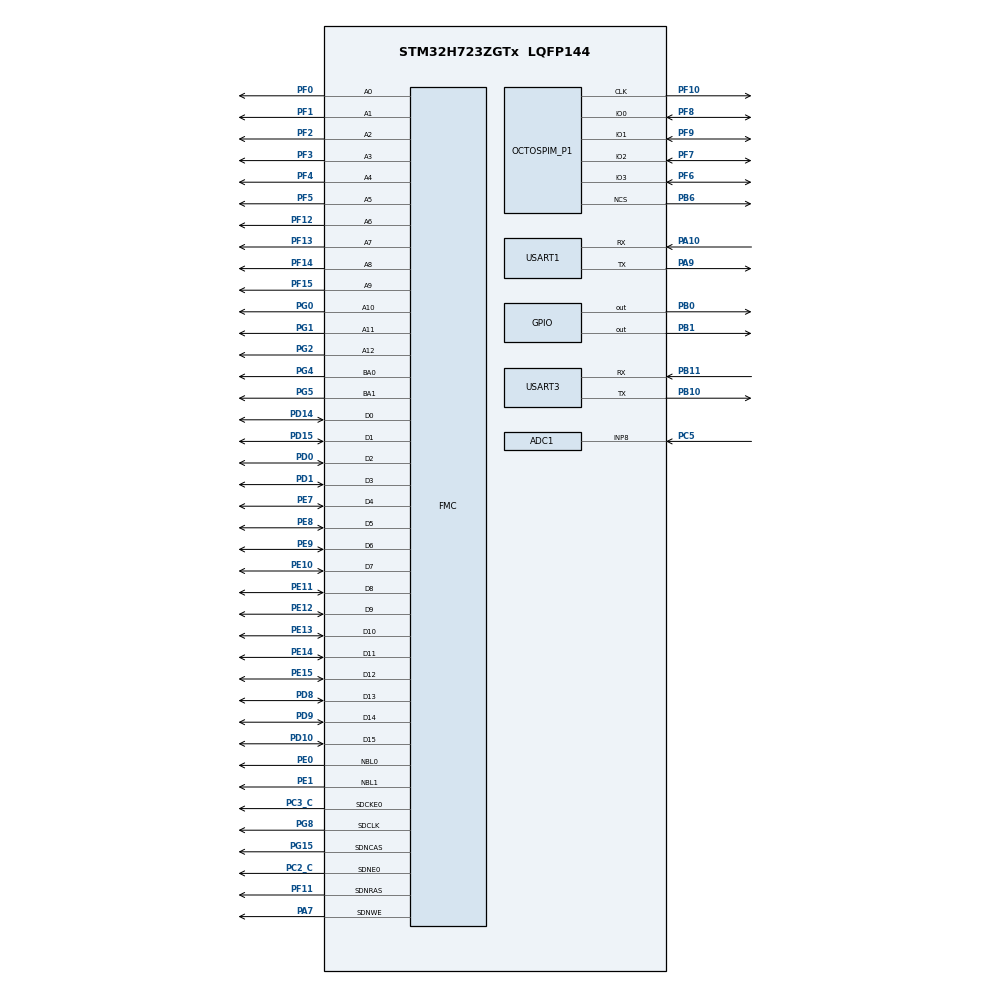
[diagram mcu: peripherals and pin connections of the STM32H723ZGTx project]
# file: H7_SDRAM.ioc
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ADC1.Channel-0\#ChannelRegularConversion=ADC_CHANNEL_8
ADC1.ClockPrescaler=ADC_CLOCK_ASYNC_DIV4
ADC1.ConversionDataManagement=ADC_CONVERSIONDATA_DMA_CIRCULAR
ADC1.ExternalTrigConv=ADC_EXTERNALTRIG_T3_TRGO
ADC1.NbrOfConversionFlag=1
ADC1.OffsetNumber-0\#ChannelRegularConversion=ADC_OFFSET_NONE
ADC1.OffsetSignedSaturation-0\#ChannelRegularConversion=DISABLE
ADC1.Rank-0\#ChannelRegularConversion=1
ADC1.SamplingTime-0\#ChannelRegularConversion=ADC_SAMPLETIME_8CYCLES_5
ADC1.master=1
CORTEX_M7.AccessPermission_S-Cortex_Memory_Protection_Unit_Region1_Settings_S=MPU_REGION_FULL_ACCESS
CORTEX_M7.AccessPermission_S-Cortex_Memory_Protection_Unit_Region2_Settings_S=MPU_REGION_FULL_ACCESS
CORTEX_M7.AccessPermission_S-Cortex_Memory_Protection_Unit_Region3_Settings_S=MPU_REGION_FULL_ACCESS
CORTEX_M7.AccessPermission_S-Cortex_Memory_Protection_Unit_Region5_Settings_S=MPU_REGION_FULL_ACCESS
CORTEX_M7.AccessPermission_Spec=MPU_REGION_FULL_ACCESS
CORTEX_M7.BaseAddress_S-Cortex_Memory_Protection_Unit_Region1_Settings_S=0x60000000
CORTEX_M7.BaseAddress_S-Cortex_Memory_Protection_Unit_Region2_Settings_S=0x30000000
CORTEX_M7.BaseAddress_S-Cortex_Memory_Protection_Unit_Region3_Settings_S=0x38000000
CORTEX_M7.BaseAddress_S-Cortex_Memory_Protection_Unit_Region5_Settings_S=0xC0000000
CORTEX_M7.BaseAddress_Spec=0x24000000
CORTEX_M7.CPU_DCache=Enabled
CORTEX_M7.CPU_ICache=Enabled
CORTEX_M7.DisableExec_S-Cortex_Memory_Protection_Unit_Region1_Settings_S=MPU_INSTRUCTION_ACCESS_ENABLE
CORTEX_M7.DisableExec_S-Cortex_Memory_Protection_Unit_Region2_Settings_S=MPU_INSTRUCTION_ACCESS_ENABLE
CORTEX_M7.DisableExec_S-Cortex_Memory_Protection_Unit_Region3_Settings_S=MPU_INSTRUCTION_ACCESS_ENABLE
CORTEX_M7.DisableExec_Spec=MPU_INSTRUCTION_ACCESS_ENABLE
CORTEX_M7.Enable_S-Cortex_Memory_Protection_Unit_Region1_Settings_S=MPU_REGION_ENABLE
CORTEX_M7.Enable_S-Cortex_Memory_Protection_Unit_Region2_Settings_S=MPU_REGION_ENABLE
CORTEX_M7.Enable_S-Cortex_Memory_Protection_Unit_Region3_Settings_S=MPU_REGION_ENABLE
CORTEX_M7.Enable_S-Cortex_Memory_Protection_Unit_Region4_Settings_S=__NULL
CORTEX_M7.Enable_S-Cortex_Memory_Protection_Unit_Region5_Settings_S=MPU_REGION_ENABLE
CORTEX_M7.IsBufferable_S-Cortex_Memory_Protection_Unit_Region1_Settings_S=MPU_ACCESS_BUFFERABLE
CORTEX_M7.IsBufferable_S-Cortex_Memory_Protection_Unit_Region2_Settings_S=MPU_ACCESS_BUFFERABLE
CORTEX_M7.IsBufferable_Spec=MPU_ACCESS_BUFFERABLE
CORTEX_M7.IsCacheable_S-Cortex_Memory_Protection_Unit_Region1_Settings_S=MPU_ACCESS_NOT_CACHEABLE
CORTEX_M7.IsCacheable_S-Cortex_Memory_Protection_Unit_Region2_Settings_S=MPU_ACCESS_CACHEABLE
CORTEX_M7.IsCacheable_S-Cortex_Memory_Protection_Unit_Region3_Settings_S=MPU_ACCESS_CACHEABLE
CORTEX_M7.IsCacheable_S-Cortex_Memory_Protection_Unit_Region5_Settings_S=MPU_ACCESS_CACHEABLE
CORTEX_M7.IsCacheable_Spec=MPU_ACCESS_CACHEABLE
CORTEX_M7.IsShareable_Spec=MPU_ACCESS_NOT_SHAREABLE
CORTEX_M7.Size_S-Cortex_Memory_Protection_Unit_Region1_Settings_S=MPU_REGION_SIZE_64KB
CORTEX_M7.Size_S-Cortex_Memory_Protection_Unit_Region2_Settings_S=MPU_REGION_SIZE_64KB
CORTEX_M7.Size_S-Cortex_Memory_Protection_Unit_Region3_Settings_S=MPU_REGION_SIZE_64KB
CORTEX_M7.Size_S-Cortex_Memory_Protection_Unit_Region5_Settings_S=MPU_REGION_SIZE_32MB
CORTEX_M7.Size_Spec=MPU_REGION_SIZE_512KB
CORTEX_M7.SubRegionDisable_S-Cortex_Memory_Protection_Unit_Region1_Settings_S=0x00
CORTEX_M7.SubRegionDisable_Spec=0xE0
CORTEX_M7.TypeExtField_S-Cortex_Memory_Protection_Unit_Region1_Settings_S=MPU_TEX_LEVEL1
CORTEX_M7.TypeExtField_S-Cortex_Memory_Protection_Unit_Region5_Settings_S=MPU_TEX_LEVEL1
CORTEX_M7.TypeExtField_Spec=MPU_TEX_LEVEL1
CORTEX_M7.default_mode_Activation=1
Dma.ADC1.0.Direction=DMA_PERIPH_TO_MEMORY
Dma.ADC1.0.EventEnable=DISABLE
Dma.ADC1.0.FIFOMode=DMA_FIFOMODE_DISABLE
Dma.ADC1.0.Instance=DMA1_Stream0
Dma.ADC1.0.MemDataAlignment=DMA_MDATAALIGN_HALFWORD
Dma.ADC1.0.MemInc=DMA_MINC_ENABLE
Dma.ADC1.0.Mode=DMA_CIRCULAR
Dma.ADC1.0.PeriphDataAlignment=DMA_PDATAALIGN_HALFWORD
Dma.ADC1.0.PeriphInc=DMA_PINC_DISABLE
Dma.ADC1.0.Polarity=HAL_DMAMUX_REQ_GEN_RISING
Dma.ADC1.0.Priority=DMA_PRIORITY_LOW
Dma.ADC1.0.RequestNumber=1
Dma.ADC1.0.SignalID=NONE
Dma.ADC1.0.SyncEnable=DISABLE
Dma.ADC1.0.SyncPolarity=HAL_DMAMUX_SYNC_NO_EVENT
Dma.ADC1.0.SyncRequestNumber=1
Dma.ADC1.0.SyncSignalID=NONE
Dma.Request0=ADC1
Dma.Request1=USART1_RX
Dma.Request2=USART3_RX
Dma.USART1_RX.1.Direction=DMA_PERIPH_TO_MEMORY
Dma.USART1_RX.1.EventEnable=DISABLE
Dma.USART1_RX.1.FIFOMode=DMA_FIFOMODE_DISABLE
Dma.USART1_RX.1.Instance=DMA1_Stream1
Dma.USART1_RX.1.MemDataAlignment=DMA_MDATAALIGN_BYTE
Dma.USART1_RX.1.MemInc=DMA_MINC_ENABLE
Dma.USART1_RX.1.Mode=DMA_NORMAL
Dma.USART1_RX.1.PeriphDataAlignment=DMA_PDATAALIGN_BYTE
Dma.USART1_RX.1.PeriphInc=DMA_PINC_DISABLE
Dma.USART1_RX.1.Polarity=HAL_DMAMUX_REQ_GEN_RISING
Dma.USART1_RX.1.Priority=DMA_PRIORITY_HIGH
Dma.USART1_RX.1.RequestNumber=1
Dma.USART1_RX.1.SignalID=NONE
Dma.USART1_RX.1.SyncEnable=DISABLE
Dma.USART1_RX.1.SyncPolarity=HAL_DMAMUX_SYNC_NO_EVENT
Dma.USART1_RX.1.SyncRequestNumber=1
Dma.USART1_RX.1.SyncSignalID=NONE
Dma.USART3_RX.2.Direction=DMA_PERIPH_TO_MEMORY
Dma.USART3_RX.2.EventEnable=DISABLE
Dma.USART3_RX.2.FIFOMode=DMA_FIFOMODE_DISABLE
Dma.USART3_RX.2.Instance=DMA1_Stream2
Dma.USART3_RX.2.MemDataAlignment=DMA_MDATAALIGN_BYTE
Dma.USART3_RX.2.MemInc=DMA_MINC_ENABLE
Dma.USART3_RX.2.Mode=DMA_NORMAL
Dma.USART3_RX.2.PeriphDataAlignment=DMA_PDATAALIGN_BYTE
Dma.USART3_RX.2.PeriphInc=DMA_PINC_DISABLE
Dma.USART3_RX.2.Polarity=HAL_DMAMUX_REQ_GEN_RISING
Dma.USART3_RX.2.Priority=DMA_PRIORITY_MEDIUM
Dma.USART3_RX.2.RequestNumber=1
Dma.USART3_RX.2.SignalID=NONE
Dma.USART3_RX.2.SyncEnable=DISABLE
Dma.USART3_RX.2.SyncPolarity=HAL_DMAMUX_SYNC_NO_EVENT
Dma.USART3_RX.2.SyncRequestNumber=1
Dma.USART3_RX.2.SyncSignalID=NONE
FMC.CASLatency1=FMC_SDRAM_CAS_LATENCY_3
FMC.ColumnBitsNumber1=FMC_SDRAM_COLUMN_BITS_NUM_9
FMC.ExitSelfRefreshDelay1=10
FMC.LoadToActiveDelay1=2
FMC.RCDDelay1=2
FMC.RPDelay1=3
FMC.RPDelay2=3
FMC.ReadBurst1=FMC_SDRAM_RBURST_ENABLE
FMC.ReadPipeDelay1=FMC_SDRAM_RPIPE_DELAY_1
FMC.ReadPipeDelay2=FMC_SDRAM_RPIPE_DELAY_1
FMC.RowCycleDelay1=9
FMC.RowCycleDelay2=9
FMC.SDClockPeriod1=FMC_SDRAM_CLOCK_PERIOD_2
FMC.SelfRefreshTime1=6
FMC.WriteRecoveryTime1=4
Mcu.Family=STM32H7
Mcu.Name=STM32H723ZGTx
Mcu.Package=LQFP144
NVIC.ADC_IRQn=true\:1\:0\:true\:false\:true\:true\:true\:true
NVIC.DMA1_Stream0_IRQn=true\:0\:0\:false\:false\:true\:false\:true\:true
NVIC.DMA1_Stream1_IRQn=true\:1\:0\:true\:false\:true\:false\:true\:true
NVIC.DMA1_Stream2_IRQn=true\:0\:0\:false\:false\:true\:false\:true\:true
NVIC.PriorityGroup=NVIC_PRIORITYGROUP_4
NVIC.USART1_IRQn=true\:0\:0\:false\:false\:true\:true\:true\:true
NVIC.USART3_IRQn=true\:0\:0\:false\:false\:true\:true\:true\:true
OCTOSPI1.ChipSelectHighTime=4
OCTOSPI1.ClockPrescaler=3
OCTOSPI1.DeviceSize=23
OCTOSPI1.FifoThreshold=4
OCTOSPI1.SampleShifting=HAL_OSPI_SAMPLE_SHIFTING_HALFCYCLE
PA10.Mode=Asynchronous
PA10.Signal=USART1_RX
PA7.Signal=FMC_SDNWE
PA9.Mode=Asynchronous
PA9.Signal=USART1_TX
PB0.GPIO_Speed=GPIO_SPEED_FREQ_VERY_HIGH
PB0.PinState=GPIO_PIN_SET
PB0.Signal=GPIO_Output
PB1.GPIO_Speed=GPIO_SPEED_FREQ_VERY_HIGH
PB1.PinState=GPIO_PIN_SET
PB1.Signal=GPIO_Output
PB10.Mode=Asynchronous
PB10.Signal=USART3_TX
PB11.Mode=Asynchronous
PB11.Signal=USART3_RX
PB6.Mode=OCTOSPI1_Port1_NCS
PB6.Signal=OCTOSPIM_P1_NCS
PC14-OSC32_IN.Mode=LSE-External-Oscillator
PC14-OSC32_IN.Signal=RCC_OSC32_IN
PC15-OSC32_OUT.Mode=LSE-External-Oscillator
PC15-OSC32_OUT.Signal=RCC_OSC32_OUT
PC2_C.Mode=SdramChipSelect1_1
PC2_C.Signal=FMC_SDNE0
PC3_C.Mode=SdramChipSelect1_1
PC3_C.Signal=FMC_SDCKE0
PC5.Signal=ADCx_INP8
PD0.Signal=FMC_D2_DA2
PD1.Signal=FMC_D3_DA3
PD10.Signal=FMC_D15_DA15
PD14.Signal=FMC_D0_DA0
PD15.Signal=FMC_D1_DA1
PD8.Signal=FMC_D13_DA13
PD9.Signal=FMC_D14_DA14
PE0.Signal=FMC_NBL0
PE1.Signal=FMC_NBL1
PE10.Signal=FMC_D7_DA7
PE11.Signal=FMC_D8_DA8
PE12.Signal=FMC_D9_DA9
PE13.Signal=FMC_D10_DA10
PE14.Signal=FMC_D11_DA11
PE15.Signal=FMC_D12_DA12
PE7.Signal=FMC_D4_DA4
PE8.Signal=FMC_D5_DA5
PE9.Signal=FMC_D6_DA6
PF0.Signal=FMC_A0
PF1.Signal=FMC_A1
PF10.Mode=O1_P1_CLK
PF10.Signal=OCTOSPIM_P1_CLK
PF11.Signal=FMC_SDNRAS
PF12.Signal=FMC_A6
PF13.Signal=FMC_A7
PF14.Signal=FMC_A8
PF15.Signal=FMC_A9
PF2.Signal=FMC_A2
PF3.Signal=FMC_A3
PF4.Signal=FMC_A4
PF5.Signal=FMC_A5
PF6.Mode=OCTOSPI1_IOL_Port1L
PF6.Signal=OCTOSPIM_P1_IO3
PF7.Mode=OCTOSPI1_IOL_Port1L
PF7.Signal=OCTOSPIM_P1_IO2
PF8.Mode=OCTOSPI1_IOL_Port1L
PF8.Signal=OCTOSPIM_P1_IO0
PF9.Mode=OCTOSPI1_IOL_Port1L
PF9.Signal=OCTOSPIM_P1_IO1
PG0.Signal=FMC_A10
PG1.Signal=FMC_A11
PG15.Signal=FMC_SDNCAS
PG2.Signal=FMC_A12
PG4.Signal=FMC_A14_BA0
PG5.Signal=FMC_A15_BA1
PG8.Signal=FMC_SDCLK
PH0-OSC_IN.Mode=HSE-External-Oscillator
PH0-OSC_IN.Signal=RCC_OSC_IN
PH1-OSC_OUT.Mode=HSE-External-Oscillator
PH1-OSC_OUT.Signal=RCC_OSC_OUT
ProjectManager.HeapSize=0x4000
ProjectManager.StackSize=0x4000
ProjectManager.TargetToolchain=MDK-ARM V5.32
RCC.ADCCLockSelection=RCC_ADCCLKSOURCE_CLKP
RCC.ADCFreq_Value=64000000
RCC.APB1Freq_Value=137500000
RCC.APB2Freq_Value=137500000
RCC.APB3Freq_Value=137500000
RCC.APB4Freq_Value=137500000
RCC.CortexFreq_Value=550000000
RCC.D1PPRE=RCC_APB3_DIV2
RCC.D2PPRE1=RCC_APB1_DIV2
RCC.D2PPRE2=RCC_APB2_DIV2
RCC.D3PPRE=RCC_APB4_DIV2
RCC.DIVM1=4
RCC.DIVN1=34
RCC.DIVP1=1
RCC.HCLKFreq_Value=275000000
RCC.HPRE=RCC_HCLK_DIV2
RCC.PLL2FRACN=0
RCC.PLL3FRACN=0
RCC.PLLFRACN=3072
RCC.SYSCLKFreq_VALUE=550000000
RCC.SYSCLKSource=RCC_SYSCLKSOURCE_PLLCLK
RCC.USBFreq_Value=275000000
SH.ADCx_INP8.0=ADC1_INP8,IN8-Single-Ended
SH.FMC_A0.0=FMC_A0,13b-sda1
SH.FMC_A1.0=FMC_A1,13b-sda1
SH.FMC_A10.0=FMC_A10,13b-sda1
SH.FMC_A11.0=FMC_A11,13b-sda1
SH.FMC_A12.0=FMC_A12,13b-sda1
SH.FMC_A14_BA0.0=FMC_BA0,FourSdramBanks1
SH.FMC_A15_BA1.0=FMC_BA1,FourSdramBanks1
SH.FMC_A2.0=FMC_A2,13b-sda1
SH.FMC_A3.0=FMC_A3,13b-sda1
SH.FMC_A4.0=FMC_A4,13b-sda1
SH.FMC_A5.0=FMC_A5,13b-sda1
SH.FMC_A6.0=FMC_A6,13b-sda1
SH.FMC_A7.0=FMC_A7,13b-sda1
SH.FMC_A8.0=FMC_A8,13b-sda1
SH.FMC_A9.0=FMC_A9,13b-sda1
SH.FMC_D0_DA0.0=FMC_D0,sd-16b-d1
SH.FMC_D10_DA10.0=FMC_D10,sd-16b-d1
SH.FMC_D11_DA11.0=FMC_D11,sd-16b-d1
SH.FMC_D12_DA12.0=FMC_D12,sd-16b-d1
SH.FMC_D13_DA13.0=FMC_D13,sd-16b-d1
SH.FMC_D14_DA14.0=FMC_D14,sd-16b-d1
SH.FMC_D15_DA15.0=FMC_D15,sd-16b-d1
SH.FMC_D1_DA1.0=FMC_D1,sd-16b-d1
SH.FMC_D2_DA2.0=FMC_D2,sd-16b-d1
SH.FMC_D3_DA3.0=FMC_D3,sd-16b-d1
SH.FMC_D4_DA4.0=FMC_D4,sd-16b-d1
SH.FMC_D5_DA5.0=FMC_D5,sd-16b-d1
SH.FMC_D6_DA6.0=FMC_D6,sd-16b-d1
SH.FMC_D7_DA7.0=FMC_D7,sd-16b-d1
SH.FMC_D8_DA8.0=FMC_D8,sd-16b-d1
SH.FMC_D9_DA9.0=FMC_D9,sd-16b-d1
SH.FMC_NBL0.0=FMC_NBL0,Sd2ByteEnable1
SH.FMC_NBL1.0=FMC_NBL1,Sd2ByteEnable1
SH.FMC_SDCLK.0=FMC_SDCLK,13b-sda1
SH.FMC_SDNCAS.0=FMC_SDNCAS,13b-sda1
SH.FMC_SDNRAS.0=FMC_SDNRAS,13b-sda1
SH.FMC_SDNWE.0=FMC_SDNWE,13b-sda1
TIM3.AutoReloadPreload=TIM_AUTORELOAD_PRELOAD_ENABLE
TIM3.Period=100-1
TIM3.Prescaler=5-1
TIM3.TIM_MasterOutputTrigger=TIM_TRGO_UPDATE
USART1.VirtualMode-Asynchronous=VM_ASYNC
USART3.VirtualMode-Asynchronous=VM_ASYNC
VP_MEMORYMAP_VS_MEMORYMAP.Mode=CurAppReg
VP_OCTOSPI1_VS_quad.Mode=quad_mode
VP_TIM3_VS_ClockSourceINT.Mode=Internal
board=custom

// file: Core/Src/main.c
/* USER CODE BEGIN Header */
/**
  ******************************************************************************
  * @file           : main.c
  * @brief          : Main program body
  ******************************************************************************
  * @attention
  *
  * Copyright (c) 2026 STMicroelectronics.
  * All rights reserved.
  *
  * This software is licensed under terms that can be found in the LICENSE file
  * in the root directory of this software component.
  * If no LICENSE file comes with this software, it is provided AS-IS.
  *
  ******************************************************************************
  */
/* USER CODE END Header */
#include "main.h"
#include "adc.h"
#include "dma.h"
#include "octospi.h"
#include "tim.h"
#include "usart.h"
#include "gpio.h"
#include "fmc.h"

/* USER CODE BEGIN Includes */
#include "bspsysteam.h"

/* USER CODE END Includes */

void SystemClock_Config(void);
void PeriphCommonClock_Config(void);
static void MPU_Config(void);

int main(void)
{

  /* MPU Configuration--------------------------------------------------------*/
  MPU_Config();

  /* Enable the CPU Cache */

  /* Enable I-Cache---------------------------------------------------------*/
  SCB_EnableICache();

  /* Enable D-Cache---------------------------------------------------------*/
  SCB_EnableDCache();

  /* MCU Configuration--------------------------------------------------------*/

  /* Reset of all peripherals, Initializes the Flash interface and the Systick. */
  HAL_Init();

  /* Configure the system clock */
  SystemClock_Config();

  /* Configure the peripherals common clocks */
  PeriphCommonClock_Config();

  /* Initialize all configured peripherals */
  MX_GPIO_Init();
  MX_DMA_Init();
  MX_FMC_Init();
  MX_OCTOSPI1_Init();
  MX_USART1_UART_Init();
  MX_TIM3_Init();
  MX_ADC1_Init();
  MX_USART3_UART_Init();
  /* USER CODE BEGIN 2 */
	SRAM_Clock_Enable();    // 如果这个函数确实还需要，放在时钟后

  /* USER CODE END 2 */

  /* Infinite loop */
  /* USER CODE BEGIN WHILE */
	scheduler_Init();
	HAL_ADC_Start_DMA(&hadc1, (uint32_t *)ADC_data, ADC_LEN);
	HAL_TIM_Base_Start(&htim3);
	HAL_Delay(1000);
	blue_Init();
//	blue_send_str("data_action");
//	blue_send_data(ADC_data,ADC_LEN);
	blue_send_str("blue_ok\r\n");
  while (1)
  {
    /* USER CODE END WHILE */

    /* USER CODE BEGIN 3 */
scheduler_run();

  }
  /* USER CODE END 3 */
}

void SystemClock_Config(void)
{
  RCC_OscInitTypeDef RCC_OscInitStruct = {0};
  RCC_ClkInitTypeDef RCC_ClkInitStruct = {0};

  /** Supply configuration update enable
  */
  HAL_PWREx_ConfigSupply(PWR_LDO_SUPPLY);

  /** Configure the main internal regulator output voltage
  */
  __HAL_PWR_VOLTAGESCALING_CONFIG(PWR_REGULATOR_VOLTAGE_SCALE0);

  while(!__HAL_PWR_GET_FLAG(PWR_FLAG_VOSRDY)) {}

  /** Initializes the RCC Oscillators according to the specified parameters
  * in the RCC_OscInitTypeDef structure.
  */
  RCC_OscInitStruct.OscillatorType = RCC_OSCILLATORTYPE_HSI;
  RCC_OscInitStruct.HSIState = RCC_HSI_DIV1;
  RCC_OscInitStruct.HSICalibrationValue = 64;
  RCC_OscInitStruct.PLL.PLLState = RCC_PLL_ON;
  RCC_OscInitStruct.PLL.PLLSource = RCC_PLLSOURCE_HSI;
  RCC_OscInitStruct.PLL.PLLM = 4;
  RCC_OscInitStruct.PLL.PLLN = 34;
  RCC_OscInitStruct.PLL.PLLP = 1;
  RCC_OscInitStruct.PLL.PLLQ = 2;
  RCC_OscInitStruct.PLL.PLLR = 2;
  RCC_OscInitStruct.PLL.PLLRGE = RCC_PLL1VCIRANGE_3;
  RCC_OscInitStruct.PLL.PLLVCOSEL = RCC_PLL1VCOWIDE;
  RCC_OscInitStruct.PLL.PLLFRACN = 3072;
  if (HAL_RCC_OscConfig(&RCC_OscInitStruct) != HAL_OK)
  {
    Error_Handler();
  }

  /** Initializes the CPU, AHB and APB buses clocks
  */
  RCC_ClkInitStruct.ClockType = RCC_CLOCKTYPE_HCLK|RCC_CLOCKTYPE_SYSCLK
                              |RCC_CLOCKTYPE_PCLK1|RCC_CLOCKTYPE_PCLK2
                              |RCC_CLOCKTYPE_D3PCLK1|RCC_CLOCKTYPE_D1PCLK1;
  RCC_ClkInitStruct.SYSCLKSource = RCC_SYSCLKSOURCE_PLLCLK;
  RCC_ClkInitStruct.SYSCLKDivider = RCC_SYSCLK_DIV1;
  RCC_ClkInitStruct.AHBCLKDivider = RCC_HCLK_DIV2;
  RCC_ClkInitStruct.APB3CLKDivider = RCC_APB3_DIV2;
  RCC_ClkInitStruct.APB1CLKDivider = RCC_APB1_DIV2;
  RCC_ClkInitStruct.APB2CLKDivider = RCC_APB2_DIV2;
  RCC_ClkInitStruct.APB4CLKDivider = RCC_APB4_DIV2;

  if (HAL_RCC_ClockConfig(&RCC_ClkInitStruct, FLASH_LATENCY_3) != HAL_OK)
  {
    Error_Handler();
  }
}

void PeriphCommonClock_Config(void)
{
  RCC_PeriphCLKInitTypeDef PeriphClkInitStruct = {0};

  /** Initializes the peripherals clock
  */
  PeriphClkInitStruct.PeriphClockSelection = RCC_PERIPHCLK_CKPER;
  PeriphClkInitStruct.CkperClockSelection = RCC_CLKPSOURCE_HSI;
  if (HAL_RCCEx_PeriphCLKConfig(&PeriphClkInitStruct) != HAL_OK)
  {
    Error_Handler();
  }
}

 /* MPU Configuration */

void MPU_Config(void)
{
  MPU_Region_InitTypeDef MPU_InitStruct = {0};

  /* Disables the MPU */
  HAL_MPU_Disable();

  /** Initializes and configures the Region and the memory to be protected
  */
  MPU_InitStruct.Enable = MPU_REGION_ENABLE;
  MPU_InitStruct.Number = MPU_REGION_NUMBER0;
  MPU_InitStruct.BaseAddress = 0x24000000;
  MPU_InitStruct.Size = MPU_REGION_SIZE_512KB;
  MPU_InitStruct.SubRegionDisable = 0xE0;
  MPU_InitStruct.TypeExtField = MPU_TEX_LEVEL1;
  MPU_InitStruct.AccessPermission = MPU_REGION_FULL_ACCESS;
  MPU_InitStruct.DisableExec = MPU_INSTRUCTION_ACCESS_ENABLE;
  MPU_InitStruct.IsShareable = MPU_ACCESS_NOT_SHAREABLE;
  MPU_InitStruct.IsCacheable = MPU_ACCESS_CACHEABLE;
  MPU_InitStruct.IsBufferable = MPU_ACCESS_BUFFERABLE;

  HAL_MPU_ConfigRegion(&MPU_InitStruct);

  /** Initializes and configures the Region and the memory to be protected
  */
  MPU_InitStruct.Number = MPU_REGION_NUMBER1;
  MPU_InitStruct.BaseAddress = 0x60000000;
  MPU_InitStruct.Size = MPU_REGION_SIZE_64KB;
  MPU_InitStruct.SubRegionDisable = 0x00;
  MPU_InitStruct.IsCacheable = MPU_ACCESS_NOT_CACHEABLE;

  HAL_MPU_ConfigRegion(&MPU_InitStruct);

  /** Initializes and configures the Region and the memory to be protected
  */
  MPU_InitStruct.Number = MPU_REGION_NUMBER2;
  MPU_InitStruct.BaseAddress = 0x30000000;
  MPU_InitStruct.SubRegionDisable = 0x0;
  MPU_InitStruct.TypeExtField = MPU_TEX_LEVEL0;
  MPU_InitStruct.IsCacheable = MPU_ACCESS_CACHEABLE;

  HAL_MPU_ConfigRegion(&MPU_InitStruct);

  /** Initializes and configures the Region and the memory to be protected
  */
  MPU_InitStruct.Number = MPU_REGION_NUMBER3;
  MPU_InitStruct.BaseAddress = 0x38000000;
  MPU_InitStruct.IsBufferable = MPU_ACCESS_NOT_BUFFERABLE;

  HAL_MPU_ConfigRegion(&MPU_InitStruct);

  /** Initializes and configures the Region and the memory to be protected
  */
  MPU_InitStruct.Number = MPU_REGION_NUMBER5;
  MPU_InitStruct.BaseAddress = 0xC0000000;
  MPU_InitStruct.Size = MPU_REGION_SIZE_32MB;
  MPU_InitStruct.TypeExtField = MPU_TEX_LEVEL1;

  HAL_MPU_ConfigRegion(&MPU_InitStruct);
  /* Enables the MPU */
  HAL_MPU_Enable(MPU_PRIVILEGED_DEFAULT);

}

void Error_Handler(void)
{
  /* USER CODE BEGIN Error_Handler_Debug */
  /* User can add his own implementation to report the HAL error return state */
  __disable_irq();
  while (1)
  {
		HAL_GPIO_TogglePin(GPIOB, GPIO_PIN_0);
        HAL_Delay(100);
  }
  /* USER CODE END Error_Handler_Debug */
}
